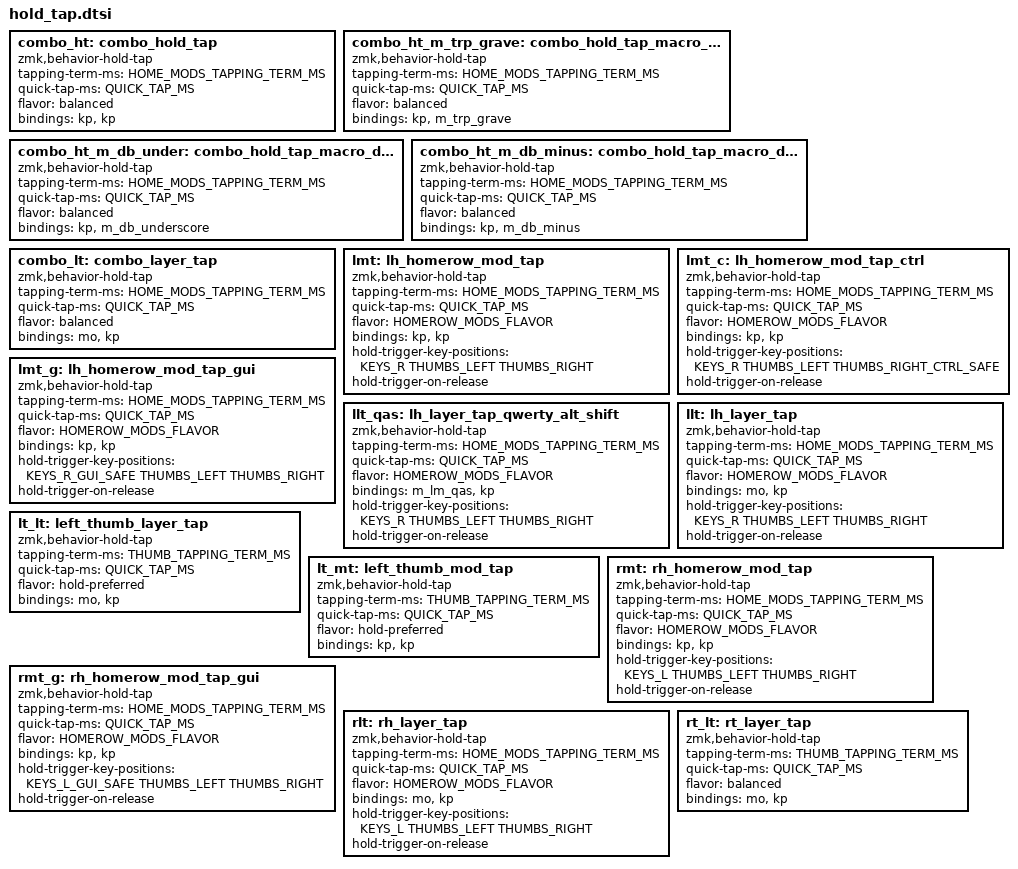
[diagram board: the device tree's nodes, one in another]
// Hold-Tap Behavior definitions
// https://zmk.dev/docs/behaviors/hold-tap
// https://zmk.dev/docs/config/behaviors#hold-tap

#pragma once

#include "key_positions.dtsi"
#include "macros.dtsi"

#define DEFAULT_TAPPING_TERM_MS 200
#define THUMB_TAPPING_TERM_MS 300
#define HOME_MODS_TAPPING_TERM_MS 300
#define QUICK_TAP_MS 200
#define HOMEROW_MODS_FLAVOR "balanced"

// Hold-taps using zero-parameter mod-morphs or macros in their `bindings` can
// accept a dummy parameter, `0`.
// https://zmk.dev/docs/keymaps/behaviors/hold-tap#using-different-behavior-types-with-hold-taps
#define HT_NO 0

// This hold-tap behavior is used for combos that contain mod-tap keys to mimic
// a QMK-style tap-only combo.
// Binding a combo's hold behavior to trigger the same modifiers
// as the home row mods for the combo's key positions is the best ZMK allows
// right now to mimic a tap-only combo.
combo_ht: combo_hold_tap {
  compatible = "zmk,behavior-hold-tap";
  #binding-cells = <2>;
  tapping-term-ms = <HOME_MODS_TAPPING_TERM_MS>;
  quick-tap-ms = <QUICK_TAP_MS>;
  flavor = "balanced";
  bindings = <&kp>, <&kp>;
};

combo_ht_m_trp_grave: combo_hold_tap_macro_triple_grave {
  compatible = "zmk,behavior-hold-tap";
  #binding-cells = <2>;
  tapping-term-ms = <HOME_MODS_TAPPING_TERM_MS>;
  quick-tap-ms = <QUICK_TAP_MS>;
  flavor = "balanced";
  bindings = <&kp>, <&m_trp_grave>;
};

combo_ht_m_db_under: combo_hold_tap_macro_double_underscore {
  compatible = "zmk,behavior-hold-tap";
  #binding-cells = <2>;
  tapping-term-ms = <HOME_MODS_TAPPING_TERM_MS>;
  quick-tap-ms = <QUICK_TAP_MS>;
  flavor = "balanced";
  bindings = <&kp>, <&m_db_underscore>;
};

combo_ht_m_db_minus: combo_hold_tap_macro_double_minus {
  compatible = "zmk,behavior-hold-tap";
  #binding-cells = <2>;
  tapping-term-ms = <HOME_MODS_TAPPING_TERM_MS>;
  quick-tap-ms = <QUICK_TAP_MS>;
  flavor = "balanced";
  bindings = <&kp>, <&m_db_minus>;
};

combo_lt: combo_layer_tap {
  compatible = "zmk,behavior-hold-tap";
  #binding-cells = <2>;
  tapping-term-ms = <HOME_MODS_TAPPING_TERM_MS>;
  quick-tap-ms = <QUICK_TAP_MS>;
  flavor = "balanced";
  bindings = <&mo>, <&kp>;
};

lmt: lh_homerow_mod_tap {
  compatible = "zmk,behavior-hold-tap";
  #binding-cells = <2>;
  tapping-term-ms = <HOME_MODS_TAPPING_TERM_MS>;
  quick-tap-ms = <QUICK_TAP_MS>;
  flavor = HOMEROW_MODS_FLAVOR;
  bindings = <&kp>, <&kp>;
  hold-trigger-key-positions = <KEYS_R THUMBS_LEFT THUMBS_RIGHT>;
  hold-trigger-on-release;
};

lmt_c: lh_homerow_mod_tap_ctrl {
  compatible = "zmk,behavior-hold-tap";
  #binding-cells = <2>;
  tapping-term-ms = <HOME_MODS_TAPPING_TERM_MS>;
  quick-tap-ms = <QUICK_TAP_MS>;
  flavor = HOMEROW_MODS_FLAVOR;
  bindings = <&kp>, <&kp>;
  hold-trigger-key-positions = <KEYS_R THUMBS_LEFT THUMBS_RIGHT_CTRL_SAFE>;
  hold-trigger-on-release;
};

lmt_g: lh_homerow_mod_tap_gui {
  compatible = "zmk,behavior-hold-tap";
  #binding-cells = <2>;
  tapping-term-ms = <HOME_MODS_TAPPING_TERM_MS>;
  quick-tap-ms = <QUICK_TAP_MS>;
  flavor = HOMEROW_MODS_FLAVOR;
  bindings = <&kp>, <&kp>;
  hold-trigger-key-positions = <KEYS_R_GUI_SAFE THUMBS_LEFT THUMBS_RIGHT>;
  hold-trigger-on-release;
};

llt_qas: lh_layer_tap_qwerty_alt_shift {
  compatible = "zmk,behavior-hold-tap";
  #binding-cells = <2>;
  tapping-term-ms = <HOME_MODS_TAPPING_TERM_MS>;
  quick-tap-ms = <QUICK_TAP_MS>;
  flavor = HOMEROW_MODS_FLAVOR;
  bindings = <&m_lm_qas>, <&kp>;
  hold-trigger-key-positions = <KEYS_R THUMBS_LEFT THUMBS_RIGHT>;
  hold-trigger-on-release;
};

llt: lh_layer_tap {
  compatible = "zmk,behavior-hold-tap";
  #binding-cells = <2>;
  tapping-term-ms = <HOME_MODS_TAPPING_TERM_MS>;
  quick-tap-ms = <QUICK_TAP_MS>;
  flavor = HOMEROW_MODS_FLAVOR;
  bindings = <&mo>, <&kp>;
  hold-trigger-key-positions = <KEYS_R THUMBS_LEFT THUMBS_RIGHT>;
  hold-trigger-on-release;
};

lt_lt: left_thumb_layer_tap {
  compatible = "zmk,behavior-hold-tap";
  #binding-cells = <2>;
  tapping-term-ms = <THUMB_TAPPING_TERM_MS>;
  quick-tap-ms = <QUICK_TAP_MS>;
  // "hold-preferred" because in my layout, left thumb is most likely a hold key
  // if it's rolled with another keypress.
  flavor = "hold-preferred";
  bindings = <&mo>, <&kp>;
};

lt_mt: left_thumb_mod_tap {
  compatible = "zmk,behavior-hold-tap";
  #binding-cells = <2>;
  tapping-term-ms = <THUMB_TAPPING_TERM_MS>;
  quick-tap-ms = <QUICK_TAP_MS>;
  // "hold-preferred" because in my layout, left thumb is most likely a hold key
  // if it's rolled with another keypress.
  flavor = "hold-preferred";
  bindings = <&kp>, <&kp>;
};

rmt: rh_homerow_mod_tap {
  compatible = "zmk,behavior-hold-tap";
  #binding-cells = <2>;
  tapping-term-ms = <HOME_MODS_TAPPING_TERM_MS>;
  quick-tap-ms = <QUICK_TAP_MS>;
  flavor = HOMEROW_MODS_FLAVOR;
  bindings = <&kp>, <&kp>;
  hold-trigger-key-positions = <KEYS_L THUMBS_LEFT THUMBS_RIGHT>;
  hold-trigger-on-release;
};

rmt_g: rh_homerow_mod_tap_gui {
  compatible = "zmk,behavior-hold-tap";
  #binding-cells = <2>;
  tapping-term-ms = <HOME_MODS_TAPPING_TERM_MS>;
  quick-tap-ms = <QUICK_TAP_MS>;
  flavor = HOMEROW_MODS_FLAVOR;
  bindings = <&kp>, <&kp>;
  hold-trigger-key-positions = <KEYS_L_GUI_SAFE THUMBS_LEFT THUMBS_RIGHT>;
  hold-trigger-on-release;
};

rlt: rh_layer_tap {
  compatible = "zmk,behavior-hold-tap";
  #binding-cells = <2>;
  tapping-term-ms = <HOME_MODS_TAPPING_TERM_MS>;
  quick-tap-ms = <QUICK_TAP_MS>;
  flavor = HOMEROW_MODS_FLAVOR;
  bindings = <&mo>, <&kp>;
  hold-trigger-key-positions = <KEYS_L THUMBS_LEFT THUMBS_RIGHT>;
  hold-trigger-on-release;
};

rt_lt: rt_layer_tap {
  compatible = "zmk,behavior-hold-tap";
  #binding-cells = <2>;
  tapping-term-ms = <THUMB_TAPPING_TERM_MS>;
  quick-tap-ms = <QUICK_TAP_MS>;
  // Set to balanced because right thumb is also space, a commonly tapped key
  flavor = "balanced";
  bindings = <&mo>, <&kp>;
};
